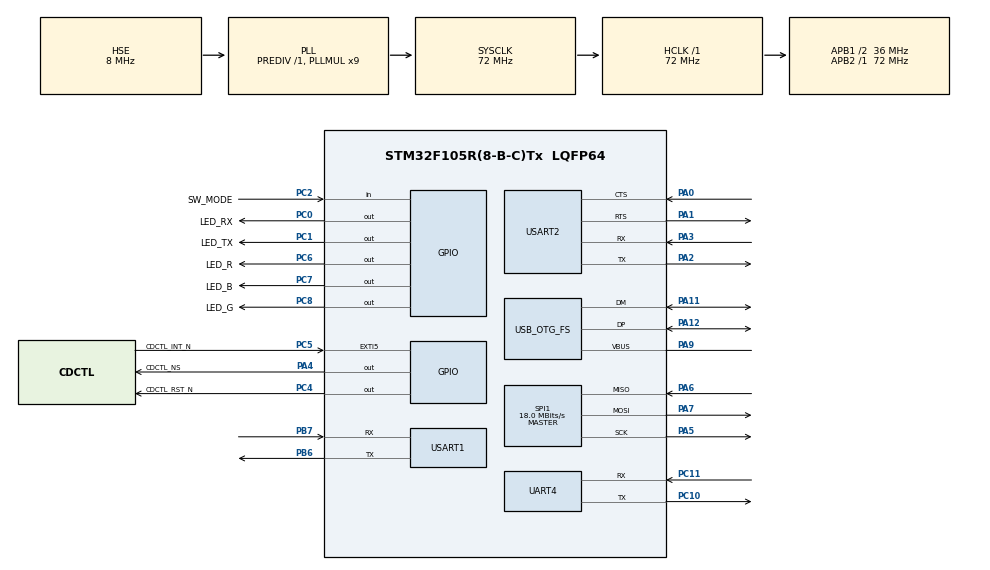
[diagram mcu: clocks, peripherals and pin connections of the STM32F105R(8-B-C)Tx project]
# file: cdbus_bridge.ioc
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ADC1.Channel-4\#ChannelRegularConversion=ADC_CHANNEL_VREFINT
ADC1.ContinuousConvMode=DISABLE
ADC1.DataAlign=ADC_DATAALIGN_RIGHT
ADC1.DiscontinuousConvMode=DISABLE
ADC1.EnableAnalogWatchDog=false
ADC1.EnableRegularConversion=ENABLE
ADC1.ExternalTrigConv=ADC_SOFTWARE_START
ADC1.InjNumberOfConversion=0
ADC1.NbrOfConversion=1
ADC1.NbrOfConversionFlag=1
ADC1.Rank-4\#ChannelRegularConversion=1
ADC1.SamplingTime-4\#ChannelRegularConversion=ADC_SAMPLETIME_1CYCLE_5
ADC1.ScanConvMode=ADC_SCAN_DISABLE
ADC1.master=1
Dma.Request0=USART1_TX
Dma.Request1=USART1_RX
Dma.Request2=USART2_RX
Dma.Request3=USART2_TX
Dma.Request4=SPI1_RX
Dma.Request5=SPI1_TX
Dma.Request6=UART4_TX
Dma.SPI1_RX.4.Direction=DMA_PERIPH_TO_MEMORY
Dma.SPI1_RX.4.Instance=DMA1_Channel2
Dma.SPI1_RX.4.MemDataAlignment=DMA_MDATAALIGN_BYTE
Dma.SPI1_RX.4.MemInc=DMA_MINC_ENABLE
Dma.SPI1_RX.4.Mode=DMA_NORMAL
Dma.SPI1_RX.4.PeriphDataAlignment=DMA_PDATAALIGN_BYTE
Dma.SPI1_RX.4.PeriphInc=DMA_PINC_DISABLE
Dma.SPI1_RX.4.Priority=DMA_PRIORITY_LOW
Dma.SPI1_TX.5.Direction=DMA_MEMORY_TO_PERIPH
Dma.SPI1_TX.5.Instance=DMA1_Channel3
Dma.SPI1_TX.5.MemDataAlignment=DMA_MDATAALIGN_BYTE
Dma.SPI1_TX.5.MemInc=DMA_MINC_ENABLE
Dma.SPI1_TX.5.Mode=DMA_NORMAL
Dma.SPI1_TX.5.PeriphDataAlignment=DMA_PDATAALIGN_BYTE
Dma.SPI1_TX.5.PeriphInc=DMA_PINC_DISABLE
Dma.SPI1_TX.5.Priority=DMA_PRIORITY_LOW
Dma.UART4_TX.6.Direction=DMA_MEMORY_TO_PERIPH
Dma.UART4_TX.6.Instance=DMA2_Channel5
Dma.UART4_TX.6.MemDataAlignment=DMA_MDATAALIGN_BYTE
Dma.UART4_TX.6.MemInc=DMA_MINC_ENABLE
Dma.UART4_TX.6.Mode=DMA_NORMAL
Dma.UART4_TX.6.PeriphDataAlignment=DMA_PDATAALIGN_BYTE
Dma.UART4_TX.6.PeriphInc=DMA_PINC_DISABLE
Dma.UART4_TX.6.Priority=DMA_PRIORITY_LOW
Dma.USART1_RX.1.Direction=DMA_PERIPH_TO_MEMORY
Dma.USART1_RX.1.Instance=DMA1_Channel5
Dma.USART1_RX.1.MemDataAlignment=DMA_MDATAALIGN_BYTE
Dma.USART1_RX.1.MemInc=DMA_MINC_ENABLE
Dma.USART1_RX.1.Mode=DMA_NORMAL
Dma.USART1_RX.1.PeriphDataAlignment=DMA_PDATAALIGN_BYTE
Dma.USART1_RX.1.PeriphInc=DMA_PINC_DISABLE
Dma.USART1_RX.1.Priority=DMA_PRIORITY_HIGH
Dma.USART1_TX.0.Direction=DMA_MEMORY_TO_PERIPH
Dma.USART1_TX.0.Instance=DMA1_Channel4
Dma.USART1_TX.0.MemDataAlignment=DMA_MDATAALIGN_BYTE
Dma.USART1_TX.0.MemInc=DMA_MINC_ENABLE
Dma.USART1_TX.0.Mode=DMA_NORMAL
Dma.USART1_TX.0.PeriphDataAlignment=DMA_PDATAALIGN_BYTE
Dma.USART1_TX.0.PeriphInc=DMA_PINC_DISABLE
Dma.USART1_TX.0.Priority=DMA_PRIORITY_LOW
Dma.USART2_RX.2.Direction=DMA_PERIPH_TO_MEMORY
Dma.USART2_RX.2.Instance=DMA1_Channel6
Dma.USART2_RX.2.MemDataAlignment=DMA_MDATAALIGN_BYTE
Dma.USART2_RX.2.MemInc=DMA_MINC_ENABLE
Dma.USART2_RX.2.Mode=DMA_NORMAL
Dma.USART2_RX.2.PeriphDataAlignment=DMA_PDATAALIGN_BYTE
Dma.USART2_RX.2.PeriphInc=DMA_PINC_DISABLE
Dma.USART2_RX.2.Priority=DMA_PRIORITY_MEDIUM
Dma.USART2_TX.3.Direction=DMA_MEMORY_TO_PERIPH
Dma.USART2_TX.3.Instance=DMA1_Channel7
Dma.USART2_TX.3.MemDataAlignment=DMA_MDATAALIGN_BYTE
Dma.USART2_TX.3.MemInc=DMA_MINC_ENABLE
Dma.USART2_TX.3.Mode=DMA_NORMAL
Dma.USART2_TX.3.PeriphDataAlignment=DMA_PDATAALIGN_BYTE
Dma.USART2_TX.3.PeriphInc=DMA_PINC_DISABLE
Dma.USART2_TX.3.Priority=DMA_PRIORITY_LOW
Mcu.Family=STM32F1
Mcu.Name=STM32F105R(8-B-C)Tx
Mcu.Package=LQFP64
NVIC.DMA1_Channel2_IRQn=true\:1\:1\:true\:false\:true\:false
NVIC.DMA1_Channel3_IRQn=true\:1\:0\:true\:false\:true\:false
NVIC.DMA1_Channel4_IRQn=true\:1\:0\:true\:false\:true\:false
NVIC.DMA1_Channel5_IRQn=true\:1\:0\:true\:false\:true\:false
NVIC.DMA1_Channel6_IRQn=true\:1\:0\:true\:false\:true\:false
NVIC.DMA1_Channel7_IRQn=true\:1\:0\:true\:false\:true\:false
NVIC.DMA2_Channel5_IRQn=true\:1\:0\:true\:false\:true\:false
NVIC.EXTI9_5_IRQn=true\:1\:0\:true\:false\:true\:true
NVIC.OTG_FS_IRQn=true\:1\:0\:true\:false\:true\:false
NVIC.PriorityGroup=NVIC_PRIORITYGROUP_2
PA0-WKUP.GPIO_PuPd=GPIO_PULLUP
PA0-WKUP.Mode=CTS_RTS
PA0-WKUP.Signal=USART2_CTS
PA1.Mode=CTS_RTS
PA1.Signal=USART2_RTS
PA11.Mode=Device_Only
PA11.Signal=USB_OTG_FS_DM
PA12.Mode=Device_Only
PA12.Signal=USB_OTG_FS_DP
PA13.Mode=Serial_Wire
PA13.Signal=SYS_JTMS-SWDIO
PA14.Mode=Serial_Wire
PA14.Signal=SYS_JTCK-SWCLK
PA2.Mode=Asynchronous
PA2.Signal=USART2_TX
PA3.GPIO_PuPd=GPIO_PULLUP
PA3.Mode=Asynchronous
PA3.Signal=USART2_RX
PA4.GPIO_Label=CDCTL_NS
PA4.PinState=GPIO_PIN_SET
PA4.Signal=GPIO_Output
PA5.Mode=Full_Duplex_Master
PA5.Signal=SPI1_SCK
PA6.Mode=Full_Duplex_Master
PA6.Signal=SPI1_MISO
PA7.Mode=Full_Duplex_Master
PA7.Signal=SPI1_MOSI
PA9.Mode=Activate_VBUS
PA9.Signal=USB_OTG_FS_VBUS
PB6.Mode=Asynchronous
PB6.Signal=USART1_TX
PB7.GPIO_PuPd=GPIO_PULLUP
PB7.Mode=Asynchronous
PB7.Signal=USART1_RX
PC0.GPIO_Label=LED_RX
PC0.GPIO_ModeDefaultOutputPP=GPIO_MODE_OUTPUT_OD
PC0.PinState=GPIO_PIN_SET
PC0.Signal=GPIO_Output
PC1.GPIO_Label=LED_TX
PC1.GPIO_ModeDefaultOutputPP=GPIO_MODE_OUTPUT_OD
PC1.PinState=GPIO_PIN_SET
PC1.Signal=GPIO_Output
PC10.Mode=Asynchronous
PC10.Signal=UART4_TX
PC11.GPIO_PuPd=GPIO_PULLUP
PC11.Mode=Asynchronous
PC11.Signal=UART4_RX
PC2.GPIO_Label=SW_MODE
PC2.GPIO_PuPd=GPIO_PULLUP
PC2.Signal=GPIO_Input
PC4.GPIO_Label=CDCTL_RST_N
PC4.PinState=GPIO_PIN_SET
PC4.Signal=GPIO_Output
PC5.GPIO_Label=CDCTL_INT_N
PC5.GPIO_ModeDefaultEXTI=GPIO_MODE_IT_FALLING
PC5.Signal=GPXTI5
PC6.GPIO_Label=LED_R
PC6.GPIO_ModeDefaultOutputPP=GPIO_MODE_OUTPUT_OD
PC6.PinState=GPIO_PIN_SET
PC6.Signal=GPIO_Output
PC7.GPIO_Label=LED_B
PC7.GPIO_ModeDefaultOutputPP=GPIO_MODE_OUTPUT_OD
PC7.PinState=GPIO_PIN_SET
PC7.Signal=GPIO_Output
PC8.GPIO_Label=LED_G
PC8.GPIO_ModeDefaultOutputPP=GPIO_MODE_OUTPUT_OD
PC8.PinState=GPIO_PIN_SET
PC8.Signal=GPIO_Output
PD0-OSC_IN.Mode=HSE-External-Oscillator
PD0-OSC_IN.Signal=RCC_OSC_IN
PD1-OSC_OUT.Mode=HSE-External-Oscillator
PD1-OSC_OUT.Signal=RCC_OSC_OUT
ProjectManager.HeapSize=0x200
ProjectManager.StackSize=0x800
ProjectManager.TargetToolchain=Makefile
RCC.ADCPresc=RCC_ADCPCLK2_DIV6
RCC.AHBFreq_Value=72000000
RCC.APB1CLKDivider=RCC_HCLK_DIV2
RCC.APB1Freq_Value=36000000
RCC.APB1TimFreq_Value=72000000
RCC.APB2Freq_Value=72000000
RCC.APB2TimFreq_Value=72000000
RCC.HCLKFreq_Value=72000000
RCC.PLLMUL=RCC_PLL_MUL9
RCC.SYSCLKFreq_VALUE=72000000
RCC.SYSCLKSource=RCC_SYSCLKSOURCE_PLLCLK
RCC.USBFreq_Value=48000000
SPI1.BaudRatePrescaler=SPI_BAUDRATEPRESCALER_4
SPI1.CalculateBaudRate=18.0 MBits/s
SPI1.Direction=SPI_DIRECTION_2LINES
SPI1.Mode=SPI_MODE_MASTER
SPI1.VirtualType=VM_MASTER
UART4.VirtualMode=Asynchronous
USART1.VirtualMode=VM_ASYNC
USART2.VirtualMode=VM_ASYNC
USB_DEVICE.APP_RX_DATA_SIZE=512
USB_DEVICE.APP_TX_DATA_SIZE=512
USB_DEVICE.CLASS_NAME_FS=CDC
USB_DEVICE.VirtualMode=Cdc
USB_DEVICE.VirtualModeFS=Cdc_FS
USB_OTG_FS.VirtualMode=Device_Only
VP_ADC1_Vref_Input.Mode=IN-Vrefint
VP_USB_DEVICE_VS_USB_DEVICE_CDC_FS.Mode=CDC_FS
board=cdbus_bridge

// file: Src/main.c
/* USER CODE BEGIN Header */
/**
  ******************************************************************************
  * @file           : main.c
  * @brief          : Main program body
  ******************************************************************************
  * This notice applies to any and all portions of this file
  * that are not between comment pairs USER CODE BEGIN and
  * USER CODE END. Other portions of this file, whether
  * inserted by the user or by software development tools
  * are owned by their respective copyright owners.
  *
  * Copyright (c) 2018 STMicroelectronics International N.V.
  * All rights reserved.
  *
  * Redistribution and use in source and binary forms, with or without
  * modification, are permitted, provided that the following conditions are met:
  *
  * 1. Redistribution of source code must retain the above copyright notice,
  *    this list of conditions and the following disclaimer.
  * 2. Redistributions in binary form must reproduce the above copyright notice,
  *    this list of conditions and the following disclaimer in the documentation
  *    and/or other materials provided with the distribution.
  * 3. Neither the name of STMicroelectronics nor the names of other
  *    contributors to this software may be used to endorse or promote products
  *    derived from this software without specific written permission.
  * 4. This software, including modifications and/or derivative works of this
  *    software, must execute solely and exclusively on microcontroller or
  *    microprocessor devices manufactured by or for STMicroelectronics.
  * 5. Redistribution and use of this software other than as permitted under
  *    this license is void and will automatically terminate your rights under
  *    this license.
  *
  * THIS SOFTWARE IS PROVIDED BY STMICROELECTRONICS AND CONTRIBUTORS "AS IS"
  * AND ANY EXPRESS, IMPLIED OR STATUTORY WARRANTIES, INCLUDING, BUT NOT
  * LIMITED TO, THE IMPLIED WARRANTIES OF MERCHANTABILITY, FITNESS FOR A
  * PARTICULAR PURPOSE AND NON-INFRINGEMENT OF THIRD PARTY INTELLECTUAL PROPERTY
  * RIGHTS ARE DISCLAIMED TO THE FULLEST EXTENT PERMITTED BY LAW. IN NO EVENT
  * SHALL STMICROELECTRONICS OR CONTRIBUTORS BE LIABLE FOR ANY DIRECT, INDIRECT,
  * INCIDENTAL, SPECIAL, EXEMPLARY, OR CONSEQUENTIAL DAMAGES (INCLUDING, BUT NOT
  * LIMITED TO, PROCUREMENT OF SUBSTITUTE GOODS OR SERVICES; LOSS OF USE, DATA,
  * OR PROFITS; OR BUSINESS INTERRUPTION) HOWEVER CAUSED AND ON ANY THEORY OF
  * LIABILITY, WHETHER IN CONTRACT, STRICT LIABILITY, OR TORT (INCLUDING
  * NEGLIGENCE OR OTHERWISE) ARISING IN ANY WAY OUT OF THE USE OF THIS SOFTWARE,
  * EVEN IF ADVISED OF THE POSSIBILITY OF SUCH DAMAGE.
  *
  ******************************************************************************
  */
/* USER CODE END Header */

#include "main.h"
#include "usb_device.h"

/* USER CODE BEGIN Includes */
#include "app_main.h"

/* USER CODE END Includes */

ADC_HandleTypeDef hadc1;

SPI_HandleTypeDef hspi1;
DMA_HandleTypeDef hdma_spi1_rx;
DMA_HandleTypeDef hdma_spi1_tx;

UART_HandleTypeDef huart4;
UART_HandleTypeDef huart1;
UART_HandleTypeDef huart2;
DMA_HandleTypeDef hdma_uart4_tx;
DMA_HandleTypeDef hdma_usart1_tx;
DMA_HandleTypeDef hdma_usart1_rx;
DMA_HandleTypeDef hdma_usart2_rx;
DMA_HandleTypeDef hdma_usart2_tx;

/* USER CODE BEGIN PV */
/* Private variables ---------------------------------------------------------*/

/* USER CODE END PV */

void SystemClock_Config(void);
static void MX_GPIO_Init(void);
static void MX_DMA_Init(void);
static void MX_SPI1_Init(void);
static void MX_UART4_Init(void);
static void MX_USART1_UART_Init(void);
static void MX_USART2_UART_Init(void);
static void MX_ADC1_Init(void);
/* USER CODE BEGIN PFP */
/* Private function prototypes -----------------------------------------------*/

/* USER CODE END PFP */

int main(void)
{

  /* MCU Configuration--------------------------------------------------------*/

  /* Reset of all peripherals, Initializes the Flash interface and the Systick. */
  HAL_Init();

  /* Configure the system clock */
  SystemClock_Config();

  /* USER CODE BEGIN SysInit */
  load_conf_early();

  /* USER CODE END SysInit */

  /* Initialize all configured peripherals */
  MX_GPIO_Init();
  MX_DMA_Init();
  MX_SPI1_Init();
  MX_UART4_Init();
  MX_USART1_UART_Init();
  MX_USART2_UART_Init();
  MX_USB_DEVICE_Init();
  MX_ADC1_Init();
  /* USER CODE BEGIN 2 */
  app_main();

  /* USER CODE END 2 */

  /* Infinite loop */
  while (1)
  {

  }
}

void SystemClock_Config(void)
{
  RCC_OscInitTypeDef RCC_OscInitStruct = {0};
  RCC_ClkInitTypeDef RCC_ClkInitStruct = {0};
  RCC_PeriphCLKInitTypeDef PeriphClkInit = {0};

  /**Initializes the CPU, AHB and APB busses clocks
  */
  RCC_OscInitStruct.OscillatorType = RCC_OSCILLATORTYPE_HSE;
  RCC_OscInitStruct.HSEState = RCC_HSE_ON;
  RCC_OscInitStruct.HSEPredivValue = RCC_HSE_PREDIV_DIV1;
  RCC_OscInitStruct.HSIState = RCC_HSI_ON;
  RCC_OscInitStruct.Prediv1Source = RCC_PREDIV1_SOURCE_HSE;
  RCC_OscInitStruct.PLL.PLLState = RCC_PLL_ON;
  RCC_OscInitStruct.PLL.PLLSource = RCC_PLLSOURCE_HSE;
  RCC_OscInitStruct.PLL.PLLMUL = RCC_PLL_MUL9;
  RCC_OscInitStruct.PLL2.PLL2State = RCC_PLL_NONE;
  if (HAL_RCC_OscConfig(&RCC_OscInitStruct) != HAL_OK)
  {
    Error_Handler();
  }
  /**Initializes the CPU, AHB and APB busses clocks
  */
  RCC_ClkInitStruct.ClockType = RCC_CLOCKTYPE_HCLK|RCC_CLOCKTYPE_SYSCLK
                              |RCC_CLOCKTYPE_PCLK1|RCC_CLOCKTYPE_PCLK2;
  RCC_ClkInitStruct.SYSCLKSource = RCC_SYSCLKSOURCE_PLLCLK;
  RCC_ClkInitStruct.AHBCLKDivider = RCC_SYSCLK_DIV1;
  RCC_ClkInitStruct.APB1CLKDivider = RCC_HCLK_DIV2;
  RCC_ClkInitStruct.APB2CLKDivider = RCC_HCLK_DIV1;

  if (HAL_RCC_ClockConfig(&RCC_ClkInitStruct, FLASH_LATENCY_2) != HAL_OK)
  {
    Error_Handler();
  }
  PeriphClkInit.PeriphClockSelection = RCC_PERIPHCLK_ADC|RCC_PERIPHCLK_USB;
  PeriphClkInit.AdcClockSelection = RCC_ADCPCLK2_DIV6;
  PeriphClkInit.UsbClockSelection = RCC_USBCLKSOURCE_PLL_DIV3;
  if (HAL_RCCEx_PeriphCLKConfig(&PeriphClkInit) != HAL_OK)
  {
    Error_Handler();
  }
  /**Configure the Systick interrupt time
  */
  __HAL_RCC_PLLI2S_ENABLE();
}

static void MX_ADC1_Init(void)
{

  ADC_ChannelConfTypeDef sConfig = {0};

  /**Common config
  */
  hadc1.Instance = ADC1;
  hadc1.Init.ScanConvMode = ADC_SCAN_DISABLE;
  hadc1.Init.ContinuousConvMode = DISABLE;
  hadc1.Init.DiscontinuousConvMode = DISABLE;
  hadc1.Init.ExternalTrigConv = ADC_SOFTWARE_START;
  hadc1.Init.DataAlign = ADC_DATAALIGN_RIGHT;
  hadc1.Init.NbrOfConversion = 1;
  if (HAL_ADC_Init(&hadc1) != HAL_OK)
  {
    Error_Handler();
  }
  /**Configure Regular Channel
  */
  sConfig.Channel = ADC_CHANNEL_VREFINT;
  sConfig.Rank = ADC_REGULAR_RANK_1;
  sConfig.SamplingTime = ADC_SAMPLETIME_1CYCLE_5;
  if (HAL_ADC_ConfigChannel(&hadc1, &sConfig) != HAL_OK)
  {
    Error_Handler();
  }

}

static void MX_SPI1_Init(void)
{

  /* SPI1 parameter configuration*/
  hspi1.Instance = SPI1;
  hspi1.Init.Mode = SPI_MODE_MASTER;
  hspi1.Init.Direction = SPI_DIRECTION_2LINES;
  hspi1.Init.DataSize = SPI_DATASIZE_8BIT;
  hspi1.Init.CLKPolarity = SPI_POLARITY_LOW;
  hspi1.Init.CLKPhase = SPI_PHASE_1EDGE;
  hspi1.Init.NSS = SPI_NSS_SOFT;
  hspi1.Init.BaudRatePrescaler = SPI_BAUDRATEPRESCALER_4;
  hspi1.Init.FirstBit = SPI_FIRSTBIT_MSB;
  hspi1.Init.TIMode = SPI_TIMODE_DISABLE;
  hspi1.Init.CRCCalculation = SPI_CRCCALCULATION_DISABLE;
  hspi1.Init.CRCPolynomial = 10;
  if (HAL_SPI_Init(&hspi1) != HAL_OK)
  {
    Error_Handler();
  }

}

static void MX_UART4_Init(void)
{

  huart4.Instance = UART4;
  huart4.Init.BaudRate = 115200;
  huart4.Init.WordLength = UART_WORDLENGTH_8B;
  huart4.Init.StopBits = UART_STOPBITS_1;
  huart4.Init.Parity = UART_PARITY_NONE;
  huart4.Init.Mode = UART_MODE_TX_RX;
  huart4.Init.HwFlowCtl = UART_HWCONTROL_NONE;
  huart4.Init.OverSampling = UART_OVERSAMPLING_16;
  if (HAL_UART_Init(&huart4) != HAL_OK)
  {
    Error_Handler();
  }

}

static void MX_USART1_UART_Init(void)
{

  huart1.Instance = USART1;
  huart1.Init.BaudRate = 115200;
  huart1.Init.WordLength = UART_WORDLENGTH_8B;
  huart1.Init.StopBits = UART_STOPBITS_1;
  huart1.Init.Parity = UART_PARITY_NONE;
  huart1.Init.Mode = UART_MODE_TX_RX;
  huart1.Init.HwFlowCtl = UART_HWCONTROL_NONE;
  huart1.Init.OverSampling = UART_OVERSAMPLING_16;
  if (HAL_UART_Init(&huart1) != HAL_OK)
  {
    Error_Handler();
  }

}

static void MX_USART2_UART_Init(void)
{

  huart2.Instance = USART2;
  huart2.Init.BaudRate = 115200;
  huart2.Init.WordLength = UART_WORDLENGTH_8B;
  huart2.Init.StopBits = UART_STOPBITS_1;
  huart2.Init.Parity = UART_PARITY_NONE;
  huart2.Init.Mode = UART_MODE_TX_RX;
  huart2.Init.HwFlowCtl = UART_HWCONTROL_NONE;
  huart2.Init.OverSampling = UART_OVERSAMPLING_16;
  if (HAL_UART_Init(&huart2) != HAL_OK)
  {
    Error_Handler();
  }

}

static void MX_DMA_Init(void)
{
  /* DMA controller clock enable */
  __HAL_RCC_DMA1_CLK_ENABLE();
  __HAL_RCC_DMA2_CLK_ENABLE();

  /* DMA interrupt init */
  /* DMA1_Channel2_IRQn interrupt configuration */
  HAL_NVIC_SetPriority(DMA1_Channel2_IRQn, 1, 1);
  HAL_NVIC_EnableIRQ(DMA1_Channel2_IRQn);
  /* DMA1_Channel3_IRQn interrupt configuration */
  HAL_NVIC_SetPriority(DMA1_Channel3_IRQn, 1, 0);
  HAL_NVIC_EnableIRQ(DMA1_Channel3_IRQn);
  /* DMA1_Channel4_IRQn interrupt configuration */
  HAL_NVIC_SetPriority(DMA1_Channel4_IRQn, 1, 0);
  HAL_NVIC_EnableIRQ(DMA1_Channel4_IRQn);
  /* DMA1_Channel5_IRQn interrupt configuration */
  HAL_NVIC_SetPriority(DMA1_Channel5_IRQn, 1, 0);
  HAL_NVIC_EnableIRQ(DMA1_Channel5_IRQn);
  /* DMA1_Channel6_IRQn interrupt configuration */
  HAL_NVIC_SetPriority(DMA1_Channel6_IRQn, 1, 0);
  HAL_NVIC_EnableIRQ(DMA1_Channel6_IRQn);
  /* DMA1_Channel7_IRQn interrupt configuration */
  HAL_NVIC_SetPriority(DMA1_Channel7_IRQn, 1, 0);
  HAL_NVIC_EnableIRQ(DMA1_Channel7_IRQn);
  /* DMA2_Channel5_IRQn interrupt configuration */
  HAL_NVIC_SetPriority(DMA2_Channel5_IRQn, 1, 0);
  HAL_NVIC_EnableIRQ(DMA2_Channel5_IRQn);

}

static void MX_GPIO_Init(void)
{
  GPIO_InitTypeDef GPIO_InitStruct = {0};

  /* GPIO Ports Clock Enable */
  __HAL_RCC_GPIOD_CLK_ENABLE();
  __HAL_RCC_GPIOC_CLK_ENABLE();
  __HAL_RCC_GPIOA_CLK_ENABLE();
  __HAL_RCC_GPIOB_CLK_ENABLE();

  /*Configure GPIO pin Output Level */
  HAL_GPIO_WritePin(GPIOC, LED_RX_Pin|LED_TX_Pin|CDCTL_RST_N_Pin|LED_R_Pin
                          |LED_B_Pin|LED_G_Pin, GPIO_PIN_SET);

  /*Configure GPIO pin Output Level */
  HAL_GPIO_WritePin(CDCTL_NS_GPIO_Port, CDCTL_NS_Pin, GPIO_PIN_SET);

  /*Configure GPIO pins : LED_RX_Pin LED_TX_Pin LED_R_Pin LED_B_Pin
                           LED_G_Pin */
  GPIO_InitStruct.Pin = LED_RX_Pin|LED_TX_Pin|LED_R_Pin|LED_B_Pin
                          |LED_G_Pin;
  GPIO_InitStruct.Mode = GPIO_MODE_OUTPUT_OD;
  GPIO_InitStruct.Pull = GPIO_NOPULL;
  GPIO_InitStruct.Speed = GPIO_SPEED_FREQ_LOW;
  HAL_GPIO_Init(GPIOC, &GPIO_InitStruct);

  /*Configure GPIO pin : SW_MODE_Pin */
  GPIO_InitStruct.Pin = SW_MODE_Pin;
  GPIO_InitStruct.Mode = GPIO_MODE_INPUT;
  GPIO_InitStruct.Pull = GPIO_PULLUP;
  HAL_GPIO_Init(SW_MODE_GPIO_Port, &GPIO_InitStruct);

  /*Configure GPIO pin : CDCTL_NS_Pin */
  GPIO_InitStruct.Pin = CDCTL_NS_Pin;
  GPIO_InitStruct.Mode = GPIO_MODE_OUTPUT_PP;
  GPIO_InitStruct.Pull = GPIO_NOPULL;
  GPIO_InitStruct.Speed = GPIO_SPEED_FREQ_HIGH;
  HAL_GPIO_Init(CDCTL_NS_GPIO_Port, &GPIO_InitStruct);

  /*Configure GPIO pin : CDCTL_RST_N_Pin */
  GPIO_InitStruct.Pin = CDCTL_RST_N_Pin;
  GPIO_InitStruct.Mode = GPIO_MODE_OUTPUT_PP;
  GPIO_InitStruct.Pull = GPIO_NOPULL;
  GPIO_InitStruct.Speed = GPIO_SPEED_FREQ_LOW;
  HAL_GPIO_Init(CDCTL_RST_N_GPIO_Port, &GPIO_InitStruct);

  /*Configure GPIO pin : CDCTL_INT_N_Pin */
  GPIO_InitStruct.Pin = CDCTL_INT_N_Pin;
  GPIO_InitStruct.Mode = GPIO_MODE_IT_FALLING;
  GPIO_InitStruct.Pull = GPIO_NOPULL;
  HAL_GPIO_Init(CDCTL_INT_N_GPIO_Port, &GPIO_InitStruct);

  /* EXTI interrupt init*/
  HAL_NVIC_SetPriority(EXTI9_5_IRQn, 1, 0);
  HAL_NVIC_EnableIRQ(EXTI9_5_IRQn);

}

void Error_Handler(void)
{
  while(1)
  {
  }
}

/************************ (C) COPYRIGHT STMicroelectronics *****END OF FILE****/
